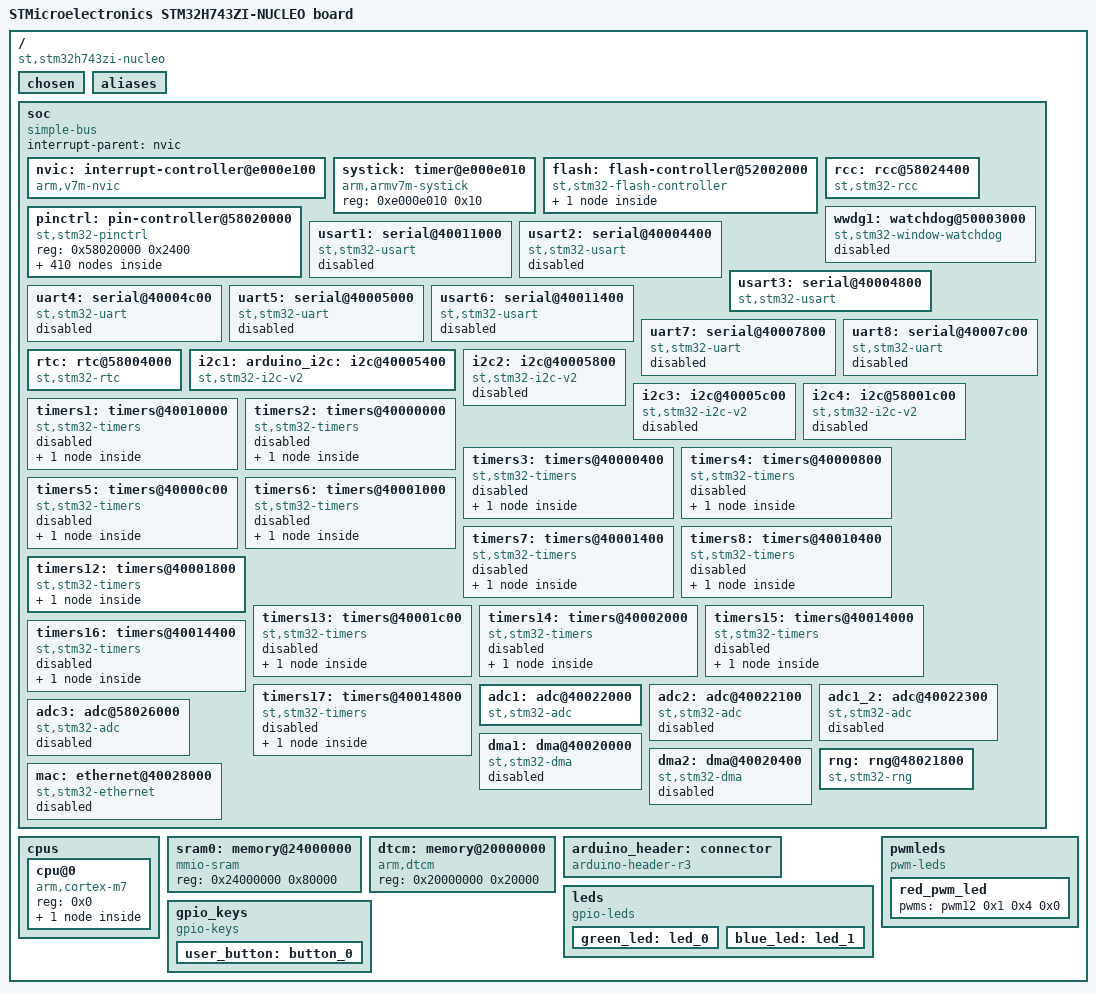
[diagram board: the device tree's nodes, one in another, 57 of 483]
/dts-v1/;

/ {
	#address-cells = < 0x1 >;
	#size-cells = < 0x1 >;
	model = "STMicroelectronics STM32H743ZI-NUCLEO board";
	compatible = "st,stm32h743zi-nucleo";
	chosen {
		zephyr,entropy = &rng;
		zephyr,flash-controller = &flash;
		zephyr,console = &usart3;
		zephyr,shell-uart = &usart3;
		zephyr,sram = &sram0;
		zephyr,flash = &flash0;
		zephyr,dtcm = &dtcm;
	};
	aliases {
		led0 = &green_led;
		led1 = &blue_led;
		pwm-led0 = &red_pwm_led;
		sw0 = &user_button;
	};
	soc {
		#address-cells = < 0x1 >;
		#size-cells = < 0x1 >;
		compatible = "simple-bus";
		interrupt-parent = < &nvic >;
		ranges;
		nvic: interrupt-controller@e000e100 {
			compatible = "arm,v7m-nvic";
			reg = < 0xe000e100 0xc00 >;
			interrupt-controller;
			#interrupt-cells = < 0x2 >;
			arm,num-irq-priority-bits = < 0x4 >;
			phandle = < 0x1 >;
		};
		systick: timer@e000e010 {
			compatible = "arm,armv7m-systick";
			reg = < 0xe000e010 0x10 >;
		};
		flash: flash-controller@52002000 {
			compatible = "st,stm32-flash-controller", "st,stm32h7-flash-controller";
			label = "FLASH_CTRL";
			reg = < 0x52002000 0x400 >;
			interrupts = < 0x4 0x0 >;
			#address-cells = < 0x1 >;
			#size-cells = < 0x1 >;
			flash0: flash@8000000 {
				compatible = "soc-nv-flash";
				label = "FLASH_STM32";
				reg = < 0x8000000 0x200000 >;
			};
		};
		rcc: rcc@58024400 {
			compatible = "st,stm32-rcc";
			#clock-cells = < 0x2 >;
			reg = < 0x58024400 0x400 >;
			label = "STM32_CLK_RCC";
			phandle = < 0x2 >;
		};
		pinctrl: pin-controller@58020000 {
			compatible = "st,stm32-pinctrl";
			#address-cells = < 0x1 >;
			#size-cells = < 0x1 >;
			reg = < 0x58020000 0x2400 >;
			gpioa: gpio@58020000 {
				compatible = "st,stm32-gpio";
				gpio-controller;
				#gpio-cells = < 0x2 >;
				reg = < 0x58020000 0x400 >;
				clocks = < &rcc 0x7 0x1 >;
				label = "GPIOA";
				phandle = < 0x9 >;
			};
			gpiob: gpio@58020400 {
				compatible = "st,stm32-gpio";
				gpio-controller;
				#gpio-cells = < 0x2 >;
				reg = < 0x58020400 0x400 >;
				clocks = < &rcc 0x7 0x2 >;
				label = "GPIOB";
				phandle = < 0xb >;
			};
			gpioc: gpio@58020800 {
				compatible = "st,stm32-gpio";
				gpio-controller;
				#gpio-cells = < 0x2 >;
				reg = < 0x58020800 0x400 >;
				clocks = < &rcc 0x7 0x4 >;
				label = "GPIOC";
				phandle = < 0xa >;
			};
			gpiod: gpio@58020C00 {
				compatible = "st,stm32-gpio";
				gpio-controller;
				#gpio-cells = < 0x2 >;
				reg = < 0x58020c00 0x400 >;
				clocks = < &rcc 0x7 0x8 >;
				label = "GPIOD";
				phandle = < 0xf >;
			};
			gpioe: gpio@58021000 {
				compatible = "st,stm32-gpio";
				gpio-controller;
				#gpio-cells = < 0x2 >;
				reg = < 0x58021000 0x400 >;
				clocks = < &rcc 0x7 0x10 >;
				label = "GPIOE";
				phandle = < 0xe >;
			};
			gpiof: gpio@58021400 {
				compatible = "st,stm32-gpio";
				gpio-controller;
				#gpio-cells = < 0x2 >;
				reg = < 0x58021400 0x400 >;
				clocks = < &rcc 0x7 0x20 >;
				label = "GPIOF";
				phandle = < 0xc >;
			};
			gpiog: gpio@58021800 {
				compatible = "st,stm32-gpio";
				gpio-controller;
				#gpio-cells = < 0x2 >;
				reg = < 0x58021800 0x400 >;
				clocks = < &rcc 0x7 0x40 >;
				label = "GPIOG";
				phandle = < 0xd >;
			};
			gpioh: gpio@58021C00 {
				compatible = "st,stm32-gpio";
				gpio-controller;
				#gpio-cells = < 0x2 >;
				reg = < 0x58021c00 0x400 >;
				clocks = < &rcc 0x7 0x80 >;
				label = "GPIOH";
			};
			gpioi: gpio@58022000 {
				compatible = "st,stm32-gpio";
				gpio-controller;
				#gpio-cells = < 0x2 >;
				reg = < 0x58022000 0x400 >;
				clocks = < &rcc 0x7 0x100 >;
				label = "GPIOI";
			};
			gpioj: gpio@58022400 {
				compatible = "st,stm32-gpio";
				gpio-controller;
				#gpio-cells = < 0x2 >;
				reg = < 0x58022400 0x400 >;
				clocks = < &rcc 0x7 0x200 >;
				label = "GPIOJ";
			};
			gpiok: gpio@58022800 {
				compatible = "st,stm32-gpio";
				gpio-controller;
				#gpio-cells = < 0x2 >;
				reg = < 0x58022800 0x400 >;
				clocks = < &rcc 0x7 0x400 >;
				label = "GPIOK";
			};
			adc1_inp16_pa0: adc1_inp16_pa0 {
				pinmux = < 0x10 >;
			};
			adc1_inn16_pa1: adc1_inn16_pa1 {
				pinmux = < 0x110 >;
			};
			adc1_inp17_pa1: adc1_inp17_pa1 {
				pinmux = < 0x110 >;
			};
			adc1_inp14_pa2: adc1_inp14_pa2 {
				pinmux = < 0x210 >;
			};
			adc1_inp15_pa3: adc1_inp15_pa3 {
				pinmux = < 0x310 >;
				phandle = < 0x8 >;
			};
			adc1_inp18_pa4: adc1_inp18_pa4 {
				pinmux = < 0x410 >;
			};
			adc1_inn18_pa5: adc1_inn18_pa5 {
				pinmux = < 0x510 >;
			};
			adc1_inp19_pa5: adc1_inp19_pa5 {
				pinmux = < 0x510 >;
			};
			adc1_inp3_pa6: adc1_inp3_pa6 {
				pinmux = < 0x610 >;
			};
			adc1_inn3_pa7: adc1_inn3_pa7 {
				pinmux = < 0x710 >;
			};
			adc1_inp7_pa7: adc1_inp7_pa7 {
				pinmux = < 0x710 >;
			};
			adc1_inn5_pb0: adc1_inn5_pb0 {
				pinmux = < 0x1010 >;
			};
			adc1_inp9_pb0: adc1_inp9_pb0 {
				pinmux = < 0x1010 >;
			};
			adc1_inp5_pb1: adc1_inp5_pb1 {
				pinmux = < 0x1110 >;
			};
			adc1_inp10_pc0: adc1_inp10_pc0 {
				pinmux = < 0x2010 >;
			};
			adc1_inn10_pc1: adc1_inn10_pc1 {
				pinmux = < 0x2110 >;
			};
			adc1_inp11_pc1: adc1_inp11_pc1 {
				pinmux = < 0x2110 >;
			};
			adc1_inp4_pc4: adc1_inp4_pc4 {
				pinmux = < 0x2410 >;
			};
			adc1_inn4_pc5: adc1_inn4_pc5 {
				pinmux = < 0x2510 >;
			};
			adc1_inp8_pc5: adc1_inp8_pc5 {
				pinmux = < 0x2510 >;
			};
			adc1_inp2_pf11: adc1_inp2_pf11 {
				pinmux = < 0x5b10 >;
			};
			adc1_inn2_pf12: adc1_inn2_pf12 {
				pinmux = < 0x5c10 >;
			};
			adc1_inp6_pf12: adc1_inp6_pf12 {
				pinmux = < 0x5c10 >;
			};
			adc2_inp14_pa2: adc2_inp14_pa2 {
				pinmux = < 0x210 >;
			};
			adc2_inp15_pa3: adc2_inp15_pa3 {
				pinmux = < 0x310 >;
			};
			adc2_inp18_pa4: adc2_inp18_pa4 {
				pinmux = < 0x410 >;
			};
			adc2_inn18_pa5: adc2_inn18_pa5 {
				pinmux = < 0x510 >;
			};
			adc2_inp19_pa5: adc2_inp19_pa5 {
				pinmux = < 0x510 >;
			};
			adc2_inp3_pa6: adc2_inp3_pa6 {
				pinmux = < 0x610 >;
			};
			adc2_inn3_pa7: adc2_inn3_pa7 {
				pinmux = < 0x710 >;
			};
			adc2_inp7_pa7: adc2_inp7_pa7 {
				pinmux = < 0x710 >;
			};
			adc2_inn5_pb0: adc2_inn5_pb0 {
				pinmux = < 0x1010 >;
			};
			adc2_inp9_pb0: adc2_inp9_pb0 {
				pinmux = < 0x1010 >;
			};
			adc2_inp5_pb1: adc2_inp5_pb1 {
				pinmux = < 0x1110 >;
			};
			adc2_inp10_pc0: adc2_inp10_pc0 {
				pinmux = < 0x2010 >;
			};
			adc2_inn10_pc1: adc2_inn10_pc1 {
				pinmux = < 0x2110 >;
			};
			adc2_inp11_pc1: adc2_inp11_pc1 {
				pinmux = < 0x2110 >;
			};
			adc2_inp4_pc4: adc2_inp4_pc4 {
				pinmux = < 0x2410 >;
			};
			adc2_inn4_pc5: adc2_inn4_pc5 {
				pinmux = < 0x2510 >;
			};
			adc2_inp8_pc5: adc2_inp8_pc5 {
				pinmux = < 0x2510 >;
			};
			adc2_inp2_pf13: adc2_inp2_pf13 {
				pinmux = < 0x5d10 >;
			};
			adc2_inn2_pf14: adc2_inn2_pf14 {
				pinmux = < 0x5e10 >;
			};
			adc2_inp6_pf14: adc2_inp6_pf14 {
				pinmux = < 0x5e10 >;
			};
			adc3_inp10_pc0: adc3_inp10_pc0 {
				pinmux = < 0x2010 >;
			};
			adc3_inn10_pc1: adc3_inn10_pc1 {
				pinmux = < 0x2110 >;
			};
			adc3_inp11_pc1: adc3_inp11_pc1 {
				pinmux = < 0x2110 >;
			};
			adc3_inn1_pc2: adc3_inn1_pc2 {
				pinmux = < 0x2210 >;
			};
			adc3_inp0_pc2: adc3_inp0_pc2 {
				pinmux = < 0x2210 >;
			};
			adc3_inp1_pc3: adc3_inp1_pc3 {
				pinmux = < 0x2310 >;
			};
			adc3_inp5_pf3: adc3_inp5_pf3 {
				pinmux = < 0x5310 >;
			};
			adc3_inn5_pf4: adc3_inn5_pf4 {
				pinmux = < 0x5410 >;
			};
			adc3_inp9_pf4: adc3_inp9_pf4 {
				pinmux = < 0x5410 >;
			};
			adc3_inp4_pf5: adc3_inp4_pf5 {
				pinmux = < 0x5510 >;
			};
			adc3_inn4_pf6: adc3_inn4_pf6 {
				pinmux = < 0x5610 >;
			};
			adc3_inp8_pf6: adc3_inp8_pf6 {
				pinmux = < 0x5610 >;
			};
			adc3_inp3_pf7: adc3_inp3_pf7 {
				pinmux = < 0x5710 >;
			};
			adc3_inn3_pf8: adc3_inn3_pf8 {
				pinmux = < 0x5810 >;
			};
			adc3_inp7_pf8: adc3_inp7_pf8 {
				pinmux = < 0x5810 >;
			};
			adc3_inp2_pf9: adc3_inp2_pf9 {
				pinmux = < 0x5910 >;
			};
			adc3_inn2_pf10: adc3_inn2_pf10 {
				pinmux = < 0x5a10 >;
			};
			adc3_inp6_pf10: adc3_inp6_pf10 {
				pinmux = < 0x5a10 >;
			};
			dac1_out1_pa4: dac1_out1_pa4 {
				pinmux = < 0x410 >;
			};
			dac1_out2_pa5: dac1_out2_pa5 {
				pinmux = < 0x510 >;
			};
			eth_col_pa3: eth_col_pa3 {
				pinmux = < 0x30b >;
				slew-rate = "very-high-speed";
			};
			eth_crs_pa0: eth_crs_pa0 {
				pinmux = < 0xb >;
				slew-rate = "very-high-speed";
			};
			eth_crs_dv_pa7: eth_crs_dv_pa7 {
				pinmux = < 0x70b >;
				slew-rate = "very-high-speed";
			};
			eth_mdc_pc1: eth_mdc_pc1 {
				pinmux = < 0x210b >;
				slew-rate = "very-high-speed";
			};
			eth_mdio_pa2: eth_mdio_pa2 {
				pinmux = < 0x20b >;
				slew-rate = "very-high-speed";
			};
			eth_pps_out_pb5: eth_pps_out_pb5 {
				pinmux = < 0x150b >;
				slew-rate = "very-high-speed";
			};
			eth_pps_out_pg8: eth_pps_out_pg8 {
				pinmux = < 0x680b >;
				slew-rate = "very-high-speed";
			};
			eth_ref_clk_pa1: eth_ref_clk_pa1 {
				pinmux = < 0x10b >;
				slew-rate = "very-high-speed";
			};
			eth_rxd0_pc4: eth_rxd0_pc4 {
				pinmux = < 0x240b >;
				slew-rate = "very-high-speed";
			};
			eth_rxd1_pc5: eth_rxd1_pc5 {
				pinmux = < 0x250b >;
				slew-rate = "very-high-speed";
			};
			eth_rxd2_pb0: eth_rxd2_pb0 {
				pinmux = < 0x100b >;
				slew-rate = "very-high-speed";
			};
			eth_rxd3_pb1: eth_rxd3_pb1 {
				pinmux = < 0x110b >;
				slew-rate = "very-high-speed";
			};
			eth_rx_clk_pa1: eth_rx_clk_pa1 {
				pinmux = < 0x10b >;
				slew-rate = "very-high-speed";
			};
			eth_rx_dv_pa7: eth_rx_dv_pa7 {
				pinmux = < 0x70b >;
				slew-rate = "very-high-speed";
			};
			eth_rx_er_pb10: eth_rx_er_pb10 {
				pinmux = < 0x1a0b >;
				slew-rate = "very-high-speed";
			};
			eth_txd0_pb12: eth_txd0_pb12 {
				pinmux = < 0x1c0b >;
				slew-rate = "very-high-speed";
			};
			eth_txd0_pg13: eth_txd0_pg13 {
				pinmux = < 0x6d0b >;
				slew-rate = "very-high-speed";
			};
			eth_txd1_pb13: eth_txd1_pb13 {
				pinmux = < 0x1d0b >;
				slew-rate = "very-high-speed";
			};
			eth_txd1_pg12: eth_txd1_pg12 {
				pinmux = < 0x6c0b >;
				slew-rate = "very-high-speed";
			};
			eth_txd1_pg14: eth_txd1_pg14 {
				pinmux = < 0x6e0b >;
				slew-rate = "very-high-speed";
			};
			eth_txd2_pc2: eth_txd2_pc2 {
				pinmux = < 0x220b >;
				slew-rate = "very-high-speed";
			};
			eth_txd3_pb8: eth_txd3_pb8 {
				pinmux = < 0x180b >;
				slew-rate = "very-high-speed";
			};
			eth_txd3_pe2: eth_txd3_pe2 {
				pinmux = < 0x420b >;
				slew-rate = "very-high-speed";
			};
			eth_tx_clk_pc3: eth_tx_clk_pc3 {
				pinmux = < 0x230b >;
				slew-rate = "very-high-speed";
			};
			eth_tx_en_pb11: eth_tx_en_pb11 {
				pinmux = < 0x1b0b >;
				slew-rate = "very-high-speed";
			};
			eth_tx_en_pg11: eth_tx_en_pg11 {
				pinmux = < 0x6b0b >;
				slew-rate = "very-high-speed";
			};
			fdcan1_rx_pa11: fdcan1_rx_pa11 {
				pinmux = < 0xb09 >;
			};
			fdcan1_rx_pb8: fdcan1_rx_pb8 {
				pinmux = < 0x1809 >;
			};
			fdcan1_rx_pd0: fdcan1_rx_pd0 {
				pinmux = < 0x3009 >;
			};
			fdcan2_rx_pb5: fdcan2_rx_pb5 {
				pinmux = < 0x1509 >;
			};
			fdcan2_rx_pb12: fdcan2_rx_pb12 {
				pinmux = < 0x1c09 >;
			};
			fdcan1_tx_pa12: fdcan1_tx_pa12 {
				pinmux = < 0xc09 >;
			};
			fdcan1_tx_pb9: fdcan1_tx_pb9 {
				pinmux = < 0x1909 >;
			};
			fdcan1_tx_pd1: fdcan1_tx_pd1 {
				pinmux = < 0x3109 >;
			};
			fdcan2_tx_pb6: fdcan2_tx_pb6 {
				pinmux = < 0x1609 >;
			};
			fdcan2_tx_pb13: fdcan2_tx_pb13 {
				pinmux = < 0x1d09 >;
			};
			i2c1_scl_pb6: i2c1_scl_pb6 {
				pinmux = < 0x1604 >;
				bias-pull-up;
				drive-open-drain;
			};
			i2c1_scl_pb8: i2c1_scl_pb8 {
				pinmux = < 0x1804 >;
				bias-pull-up;
				drive-open-drain;
				phandle = < 0x5 >;
			};
			i2c2_scl_pb10: i2c2_scl_pb10 {
				pinmux = < 0x1a04 >;
				bias-pull-up;
				drive-open-drain;
			};
			i2c2_scl_pf1: i2c2_scl_pf1 {
				pinmux = < 0x5104 >;
				bias-pull-up;
				drive-open-drain;
			};
			i2c3_scl_pa8: i2c3_scl_pa8 {
				pinmux = < 0x804 >;
				bias-pull-up;
				drive-open-drain;
			};
			i2c4_scl_pb6: i2c4_scl_pb6 {
				pinmux = < 0x1606 >;
				bias-pull-up;
				drive-open-drain;
			};
			i2c4_scl_pb8: i2c4_scl_pb8 {
				pinmux = < 0x1806 >;
				bias-pull-up;
				drive-open-drain;
			};
			i2c4_scl_pd12: i2c4_scl_pd12 {
				pinmux = < 0x3c04 >;
				bias-pull-up;
				drive-open-drain;
			};
			i2c4_scl_pf14: i2c4_scl_pf14 {
				pinmux = < 0x5e04 >;
				bias-pull-up;
				drive-open-drain;
			};
			i2c1_sda_pb7: i2c1_sda_pb7 {
				pinmux = < 0x1704 >;
				bias-pull-up;
				drive-open-drain;
			};
			i2c1_sda_pb9: i2c1_sda_pb9 {
				pinmux = < 0x1904 >;
				bias-pull-up;
				drive-open-drain;
				phandle = < 0x6 >;
			};
			i2c2_sda_pb11: i2c2_sda_pb11 {
				pinmux = < 0x1b04 >;
				bias-pull-up;
				drive-open-drain;
			};
			i2c2_sda_pf0: i2c2_sda_pf0 {
				pinmux = < 0x5004 >;
				bias-pull-up;
				drive-open-drain;
			};
			i2c3_sda_pc9: i2c3_sda_pc9 {
				pinmux = < 0x2904 >;
				bias-pull-up;
				drive-open-drain;
			};
			i2c4_sda_pb7: i2c4_sda_pb7 {
				pinmux = < 0x1706 >;
				bias-pull-up;
				drive-open-drain;
			};
			i2c4_sda_pb9: i2c4_sda_pb9 {
				pinmux = < 0x1906 >;
				bias-pull-up;
				drive-open-drain;
			};
			i2c4_sda_pd13: i2c4_sda_pd13 {
				pinmux = < 0x3d04 >;
				bias-pull-up;
				drive-open-drain;
			};
			i2c4_sda_pf15: i2c4_sda_pf15 {
				pinmux = < 0x5f04 >;
				bias-pull-up;
				drive-open-drain;
			};
			i2s1_ck_pa5: i2s1_ck_pa5 {
				pinmux = < 0x505 >;
				slew-rate = "very-high-speed";
			};
			i2s1_ck_pb3: i2s1_ck_pb3 {
				pinmux = < 0x1305 >;
				slew-rate = "very-high-speed";
			};
			i2s1_ck_pg11: i2s1_ck_pg11 {
				pinmux = < 0x6b05 >;
				slew-rate = "very-high-speed";
			};
			i2s2_ck_pa9: i2s2_ck_pa9 {
				pinmux = < 0x905 >;
				slew-rate = "very-high-speed";
			};
			i2s2_ck_pa12: i2s2_ck_pa12 {
				pinmux = < 0xc05 >;
				slew-rate = "very-high-speed";
			};
			i2s2_ck_pb10: i2s2_ck_pb10 {
				pinmux = < 0x1a05 >;
				slew-rate = "very-high-speed";
			};
			i2s2_ck_pb13: i2s2_ck_pb13 {
				pinmux = < 0x1d05 >;
				slew-rate = "very-high-speed";
			};
			i2s2_ck_pd3: i2s2_ck_pd3 {
				pinmux = < 0x3305 >;
				slew-rate = "very-high-speed";
			};
			i2s3_ck_pb3: i2s3_ck_pb3 {
				pinmux = < 0x1306 >;
				slew-rate = "very-high-speed";
			};
			i2s3_ck_pc10: i2s3_ck_pc10 {
				pinmux = < 0x2a06 >;
				slew-rate = "very-high-speed";
			};
			i2s1_ws_pa4: i2s1_ws_pa4 {
				pinmux = < 0x405 >;
			};
			i2s1_ws_pa15: i2s1_ws_pa15 {
				pinmux = < 0xf05 >;
			};
			i2s1_ws_pg10: i2s1_ws_pg10 {
				pinmux = < 0x6a05 >;
			};
			i2s2_ws_pa11: i2s2_ws_pa11 {
				pinmux = < 0xb05 >;
			};
			i2s2_ws_pb4: i2s2_ws_pb4 {
				pinmux = < 0x1407 >;
			};
			i2s2_ws_pb9: i2s2_ws_pb9 {
				pinmux = < 0x1905 >;
			};
			i2s2_ws_pb12: i2s2_ws_pb12 {
				pinmux = < 0x1c05 >;
			};
			i2s3_ws_pa4: i2s3_ws_pa4 {
				pinmux = < 0x406 >;
			};
			i2s3_ws_pa15: i2s3_ws_pa15 {
				pinmux = < 0xf06 >;
			};
			sdmmc1_ckin_pb8: sdmmc1_ckin_pb8 {
				pinmux = < 0x1807 >;
				slew-rate = "very-high-speed";
			};
			sdmmc1_d4_pb8: sdmmc1_d4_pb8 {
				pinmux = < 0x180c >;
				slew-rate = "very-high-speed";
			};
			sdmmc1_cdir_pb9: sdmmc1_cdir_pb9 {
				pinmux = < 0x1907 >;
				slew-rate = "very-high-speed";
			};
			sdmmc1_d5_pb9: sdmmc1_d5_pb9 {
				pinmux = < 0x190c >;
				slew-rate = "very-high-speed";
			};
			sdmmc1_d0dir_pc6: sdmmc1_d0dir_pc6 {
				pinmux = < 0x2608 >;
				slew-rate = "very-high-speed";
			};
			sdmmc1_d6_pc6: sdmmc1_d6_pc6 {
				pinmux = < 0x260c >;
				slew-rate = "very-high-speed";
			};
			sdmmc1_d123dir_pc7: sdmmc1_d123dir_pc7 {
				pinmux = < 0x2708 >;
				slew-rate = "very-high-speed";
			};
			sdmmc1_d7_pc7: sdmmc1_d7_pc7 {
				pinmux = < 0x270c >;
				slew-rate = "very-high-speed";
			};
			sdmmc1_d0_pc8: sdmmc1_d0_pc8 {
				pinmux = < 0x280c >;
				slew-rate = "very-high-speed";
			};
			sdmmc1_d1_pc9: sdmmc1_d1_pc9 {
				pinmux = < 0x290c >;
				slew-rate = "very-high-speed";
			};
			sdmmc1_d2_pc10: sdmmc1_d2_pc10 {
				pinmux = < 0x2a0c >;
				slew-rate = "very-high-speed";
			};
			sdmmc1_d3_pc11: sdmmc1_d3_pc11 {
				pinmux = < 0x2b0c >;
				slew-rate = "very-high-speed";
			};
			sdmmc1_ck_pc12: sdmmc1_ck_pc12 {
				pinmux = < 0x2c0c >;
				slew-rate = "very-high-speed";
			};
			sdmmc1_cmd_pd2: sdmmc1_cmd_pd2 {
				pinmux = < 0x320c >;
				slew-rate = "very-high-speed";
			};
			sdmmc2_cmd_pa0: sdmmc2_cmd_pa0 {
				pinmux = < 0x9 >;
				slew-rate = "very-high-speed";
			};
			sdmmc2_d2_pb3: sdmmc2_d2_pb3 {
				pinmux = < 0x1309 >;
				slew-rate = "very-high-speed";
			};
			sdmmc2_d3_pb4: sdmmc2_d3_pb4 {
				pinmux = < 0x1409 >;
				slew-rate = "very-high-speed";
			};
			sdmmc2_d4_pb8: sdmmc2_d4_pb8 {
				pinmux = < 0x180a >;
				slew-rate = "very-high-speed";
			};
			sdmmc2_d5_pb9: sdmmc2_d5_pb9 {
				pinmux = < 0x190a >;
				slew-rate = "very-high-speed";
			};
			sdmmc2_d0_pb14: sdmmc2_d0_pb14 {
				pinmux = < 0x1e09 >;
				slew-rate = "very-high-speed";
			};
			sdmmc2_d1_pb15: sdmmc2_d1_pb15 {
				pinmux = < 0x1f09 >;
				slew-rate = "very-high-speed";
			};
			sdmmc2_ck_pc1: sdmmc2_ck_pc1 {
				pinmux = < 0x2109 >;
				slew-rate = "very-high-speed";
			};
			sdmmc2_d6_pc6: sdmmc2_d6_pc6 {
				pinmux = < 0x260a >;
				slew-rate = "very-high-speed";
			};
			sdmmc2_d7_pc7: sdmmc2_d7_pc7 {
				pinmux = < 0x270a >;
				slew-rate = "very-high-speed";
			};
			sdmmc2_ck_pd6: sdmmc2_ck_pd6 {
				pinmux = < 0x360b >;
				slew-rate = "very-high-speed";
			};
			sdmmc2_cmd_pd7: sdmmc2_cmd_pd7 {
				pinmux = < 0x370b >;
				slew-rate = "very-high-speed";
			};
			sdmmc2_d2_pg11: sdmmc2_d2_pg11 {
				pinmux = < 0x6b0a >;
				slew-rate = "very-high-speed";
			};
			spi1_miso_pa6: spi1_miso_pa6 {
				pinmux = < 0x605 >;
				bias-pull-down;
			};
			spi1_miso_pb4: spi1_miso_pb4 {
				pinmux = < 0x1405 >;
				bias-pull-down;
			};
			spi1_miso_pg9: spi1_miso_pg9 {
				pinmux = < 0x6905 >;
				bias-pull-down;
			};
			spi2_miso_pb14: spi2_miso_pb14 {
				pinmux = < 0x1e05 >;
				bias-pull-down;
			};
			spi2_miso_pc2: spi2_miso_pc2 {
				pinmux = < 0x2205 >;
				bias-pull-down;
			};
			spi3_miso_pb4: spi3_miso_pb4 {
				pinmux = < 0x1406 >;
				bias-pull-down;
			};
			spi3_miso_pc11: spi3_miso_pc11 {
				pinmux = < 0x2b06 >;
				bias-pull-down;
			};
			spi4_miso_pe5: spi4_miso_pe5 {
				pinmux = < 0x4505 >;
				bias-pull-down;
			};
			spi4_miso_pe13: spi4_miso_pe13 {
				pinmux = < 0x4d05 >;
				bias-pull-down;
			};
			spi5_miso_pf8: spi5_miso_pf8 {
				pinmux = < 0x5805 >;
				bias-pull-down;
			};
			spi6_miso_pa6: spi6_miso_pa6 {
				pinmux = < 0x608 >;
				bias-pull-down;
			};
			spi6_miso_pb4: spi6_miso_pb4 {
				pinmux = < 0x1408 >;
				bias-pull-down;
			};
			spi6_miso_pg12: spi6_miso_pg12 {
				pinmux = < 0x6c05 >;
				bias-pull-down;
			};
			spi1_mosi_pa7: spi1_mosi_pa7 {
				pinmux = < 0x705 >;
				bias-pull-down;
			};
			spi1_mosi_pb5: spi1_mosi_pb5 {
				pinmux = < 0x1505 >;
				bias-pull-down;
			};
			spi1_mosi_pd7: spi1_mosi_pd7 {
				pinmux = < 0x3705 >;
				bias-pull-down;
			};
			spi2_mosi_pb15: spi2_mosi_pb15 {
				pinmux = < 0x1f05 >;
				bias-pull-down;
			};
			spi2_mosi_pc1: spi2_mosi_pc1 {
				pinmux = < 0x2105 >;
				bias-pull-down;
			};
			spi2_mosi_pc3: spi2_mosi_pc3 {
				pinmux = < 0x2305 >;
				bias-pull-down;
			};
			spi3_mosi_pb2: spi3_mosi_pb2 {
				pinmux = < 0x1207 >;
				bias-pull-down;
			};
			spi3_mosi_pb5: spi3_mosi_pb5 {
				pinmux = < 0x1507 >;
				bias-pull-down;
			};
			spi3_mosi_pc12: spi3_mosi_pc12 {
				pinmux = < 0x2c06 >;
				bias-pull-down;
			};
			spi3_mosi_pd6: spi3_mosi_pd6 {
				pinmux = < 0x3605 >;
				bias-pull-down;
			};
			spi4_mosi_pe6: spi4_mosi_pe6 {
				pinmux = < 0x4605 >;
				bias-pull-down;
			};
			spi4_mosi_pe14: spi4_mosi_pe14 {
				pinmux = < 0x4e05 >;
				bias-pull-down;
			};
			spi5_mosi_pf9: spi5_mosi_pf9 {
				pinmux = < 0x5905 >;
				bias-pull-down;
			};
			spi5_mosi_pf11: spi5_mosi_pf11 {
				pinmux = < 0x5b05 >;
				bias-pull-down;
			};
			spi6_mosi_pa7: spi6_mosi_pa7 {
				pinmux = < 0x708 >;
				bias-pull-down;
			};
			spi6_mosi_pb5: spi6_mosi_pb5 {
				pinmux = < 0x1508 >;
				bias-pull-down;
			};
			spi6_mosi_pg14: spi6_mosi_pg14 {
				pinmux = < 0x6e05 >;
				bias-pull-down;
			};
			spi1_nss_pa4: spi1_nss_pa4 {
				pinmux = < 0x405 >;
				bias-pull-up;
			};
			spi1_nss_pa15: spi1_nss_pa15 {
				pinmux = < 0xf05 >;
				bias-pull-up;
			};
			spi1_nss_pg10: spi1_nss_pg10 {
				pinmux = < 0x6a05 >;
				bias-pull-up;
			};
			spi2_nss_pa11: spi2_nss_pa11 {
				pinmux = < 0xb05 >;
				bias-pull-up;
			};
			spi2_nss_pb4: spi2_nss_pb4 {
				pinmux = < 0x1407 >;
				bias-pull-up;
			};
			spi2_nss_pb9: spi2_nss_pb9 {
				pinmux = < 0x1905 >;
				bias-pull-up;
			};
			spi2_nss_pb12: spi2_nss_pb12 {
				pinmux = < 0x1c05 >;
				bias-pull-up;
			};
			spi3_nss_pa4: spi3_nss_pa4 {
				pinmux = < 0x406 >;
				bias-pull-up;
			};
			spi3_nss_pa15: spi3_nss_pa15 {
				pinmux = < 0xf06 >;
				bias-pull-up;
			};
			spi4_nss_pe4: spi4_nss_pe4 {
				pinmux = < 0x4405 >;
				bias-pull-up;
			};
			spi4_nss_pe11: spi4_nss_pe11 {
				pinmux = < 0x4b05 >;
				bias-pull-up;
			};
			spi5_nss_pf6: spi5_nss_pf6 {
				pinmux = < 0x5605 >;
				bias-pull-up;
			};
			spi6_nss_pa4: spi6_nss_pa4 {
				pinmux = < 0x408 >;
				bias-pull-up;
			};
			spi6_nss_pa15: spi6_nss_pa15 {
				pinmux = < 0xf07 >;
				bias-pull-up;
			};
			spi6_nss_pg8: spi6_nss_pg8 {
				pinmux = < 0x6805 >;
				bias-pull-up;
			};
			spi1_sck_pa5: spi1_sck_pa5 {
				pinmux = < 0x505 >;
				slew-rate = "very-high-speed";
			};
			spi1_sck_pb3: spi1_sck_pb3 {
				pinmux = < 0x1305 >;
				slew-rate = "very-high-speed";
			};
			spi1_sck_pg11: spi1_sck_pg11 {
				pinmux = < 0x6b05 >;
				slew-rate = "very-high-speed";
			};
			spi2_sck_pa9: spi2_sck_pa9 {
				pinmux = < 0x905 >;
				slew-rate = "very-high-speed";
			};
			spi2_sck_pa12: spi2_sck_pa12 {
				pinmux = < 0xc05 >;
				slew-rate = "very-high-speed";
			};
			spi2_sck_pb10: spi2_sck_pb10 {
				pinmux = < 0x1a05 >;
				slew-rate = "very-high-speed";
			};
			spi2_sck_pb13: spi2_sck_pb13 {
				pinmux = < 0x1d05 >;
				slew-rate = "very-high-speed";
			};
			spi2_sck_pd3: spi2_sck_pd3 {
				pinmux = < 0x3305 >;
				slew-rate = "very-high-speed";
			};
			spi3_sck_pb3: spi3_sck_pb3 {
				pinmux = < 0x1306 >;
				slew-rate = "very-high-speed";
			};
			spi3_sck_pc10: spi3_sck_pc10 {
				pinmux = < 0x2a06 >;
				slew-rate = "very-high-speed";
			};
			spi4_sck_pe2: spi4_sck_pe2 {
				pinmux = < 0x4205 >;
				slew-rate = "very-high-speed";
			};
			spi4_sck_pe12: spi4_sck_pe12 {
				pinmux = < 0x4c05 >;
				slew-rate = "very-high-speed";
			};
			spi5_sck_pf7: spi5_sck_pf7 {
				pinmux = < 0x5705 >;
				slew-rate = "very-high-speed";
			};
			spi6_sck_pa5: spi6_sck_pa5 {
				pinmux = < 0x508 >;
				slew-rate = "very-high-speed";
			};
			spi6_sck_pb3: spi6_sck_pb3 {
				pinmux = < 0x1308 >;
				slew-rate = "very-high-speed";
			};
			spi6_sck_pg13: spi6_sck_pg13 {
				pinmux = < 0x6d05 >;
				slew-rate = "very-high-speed";
			};
			tim1_ch1n_pwm_pa7: tim1_ch1n_pwm_pa7 {
				pinmux = < 0x701 >;
			};
			tim1_ch1_pwm_pa8: tim1_ch1_pwm_pa8 {
				pinmux = < 0x801 >;
			};
			tim1_ch2_pwm_pa9: tim1_ch2_pwm_pa9 {
				pinmux = < 0x901 >;
			};
			tim1_ch3_pwm_pa10: tim1_ch3_pwm_pa10 {
				pinmux = < 0xa01 >;
			};
			tim1_ch4_pwm_pa11: tim1_ch4_pwm_pa11 {
				pinmux = < 0xb01 >;
			};
			tim1_ch2n_pwm_pb0: tim1_ch2n_pwm_pb0 {
				pinmux = < 0x1001 >;
			};
			tim1_ch3n_pwm_pb1: tim1_ch3n_pwm_pb1 {
				pinmux = < 0x1101 >;
			};
			tim1_ch1n_pwm_pb13: tim1_ch1n_pwm_pb13 {
				pinmux = < 0x1d01 >;
			};
			tim1_ch2n_pwm_pb14: tim1_ch2n_pwm_pb14 {
				pinmux = < 0x1e01 >;
			};
			tim1_ch3n_pwm_pb15: tim1_ch3n_pwm_pb15 {
				pinmux = < 0x1f01 >;
			};
			tim1_ch1n_pwm_pe8: tim1_ch1n_pwm_pe8 {
				pinmux = < 0x4801 >;
			};
			tim1_ch1_pwm_pe9: tim1_ch1_pwm_pe9 {
				pinmux = < 0x4901 >;
			};
			tim1_ch2n_pwm_pe10: tim1_ch2n_pwm_pe10 {
				pinmux = < 0x4a01 >;
			};
			tim1_ch2_pwm_pe11: tim1_ch2_pwm_pe11 {
				pinmux = < 0x4b01 >;
			};
			tim1_ch3n_pwm_pe12: tim1_ch3n_pwm_pe12 {
				pinmux = < 0x4c01 >;
			};
			tim1_ch3_pwm_pe13: tim1_ch3_pwm_pe13 {
				pinmux = < 0x4d01 >;
			};
			tim1_ch4_pwm_pe14: tim1_ch4_pwm_pe14 {
				pinmux = < 0x4e01 >;
			};
			tim2_ch1_pwm_pa0: tim2_ch1_pwm_pa0 {
				pinmux = < 0x1 >;
			};
			tim2_ch2_pwm_pa1: tim2_ch2_pwm_pa1 {
				pinmux = < 0x101 >;
			};
			tim2_ch3_pwm_pa2: tim2_ch3_pwm_pa2 {
				pinmux = < 0x201 >;
			};
			tim2_ch4_pwm_pa3: tim2_ch4_pwm_pa3 {
				pinmux = < 0x301 >;
			};
			tim2_ch1_pwm_pa5: tim2_ch1_pwm_pa5 {
				pinmux = < 0x501 >;
			};
			tim2_ch1_pwm_pa15: tim2_ch1_pwm_pa15 {
				pinmux = < 0xf01 >;
			};
			tim2_ch2_pwm_pb3: tim2_ch2_pwm_pb3 {
				pinmux = < 0x1301 >;
			};
			tim2_ch3_pwm_pb10: tim2_ch3_pwm_pb10 {
				pinmux = < 0x1a01 >;
			};
			tim2_ch4_pwm_pb11: tim2_ch4_pwm_pb11 {
				pinmux = < 0x1b01 >;
			};
			tim12_ch1_pwm_pb14: tim12_ch1_pwm_pb14 {
				pinmux = < 0x1e02 >;
				phandle = < 0x7 >;
			};
			tim12_ch2_pwm_pb15: tim12_ch2_pwm_pb15 {
				pinmux = < 0x1f02 >;
			};
			tim13_ch1_pwm_pa6: tim13_ch1_pwm_pa6 {
				pinmux = < 0x609 >;
			};
			tim3_ch1_pwm_pa6: tim3_ch1_pwm_pa6 {
				pinmux = < 0x602 >;
			};
			tim3_ch2_pwm_pa7: tim3_ch2_pwm_pa7 {
				pinmux = < 0x702 >;
			};
			tim3_ch3_pwm_pb0: tim3_ch3_pwm_pb0 {
				pinmux = < 0x1002 >;
			};
			tim3_ch4_pwm_pb1: tim3_ch4_pwm_pb1 {
				pinmux = < 0x1102 >;
			};
			tim3_ch1_pwm_pb4: tim3_ch1_pwm_pb4 {
				pinmux = < 0x1402 >;
			};
			tim3_ch2_pwm_pb5: tim3_ch2_pwm_pb5 {
				pinmux = < 0x1502 >;
			};
			tim3_ch1_pwm_pc6: tim3_ch1_pwm_pc6 {
				pinmux = < 0x2602 >;
			};
			tim3_ch2_pwm_pc7: tim3_ch2_pwm_pc7 {
				pinmux = < 0x2702 >;
			};
			tim3_ch3_pwm_pc8: tim3_ch3_pwm_pc8 {
				pinmux = < 0x2802 >;
			};
			tim3_ch4_pwm_pc9: tim3_ch4_pwm_pc9 {
				pinmux = < 0x2902 >;
			};
			tim13_ch1_pwm_pf8: tim13_ch1_pwm_pf8 {
				pinmux = < 0x5809 >;
			};
			tim14_ch1_pwm_pa7: tim14_ch1_pwm_pa7 {
				pinmux = < 0x709 >;
			};
			tim4_ch1_pwm_pb6: tim4_ch1_pwm_pb6 {
				pinmux = < 0x1602 >;
			};
			tim4_ch2_pwm_pb7: tim4_ch2_pwm_pb7 {
				pinmux = < 0x1702 >;
			};
			tim4_ch3_pwm_pb8: tim4_ch3_pwm_pb8 {
				pinmux = < 0x1802 >;
			};
			tim4_ch4_pwm_pb9: tim4_ch4_pwm_pb9 {
				pinmux = < 0x1902 >;
			};
			tim4_ch1_pwm_pd12: tim4_ch1_pwm_pd12 {
				pinmux = < 0x3c02 >;
			};
			tim4_ch2_pwm_pd13: tim4_ch2_pwm_pd13 {
				pinmux = < 0x3d02 >;
			};
			tim4_ch3_pwm_pd14: tim4_ch3_pwm_pd14 {
				pinmux = < 0x3e02 >;
			};
			tim4_ch4_pwm_pd15: tim4_ch4_pwm_pd15 {
				pinmux = < 0x3f02 >;
			};
			tim14_ch1_pwm_pf9: tim14_ch1_pwm_pf9 {
				pinmux = < 0x5909 >;
			};
			tim5_ch1_pwm_pa0: tim5_ch1_pwm_pa0 {
				pinmux = < 0x2 >;
			};
			tim15_ch1n_pwm_pa1: tim15_ch1n_pwm_pa1 {
				pinmux = < 0x104 >;
			};
			tim5_ch2_pwm_pa1: tim5_ch2_pwm_pa1 {
				pinmux = < 0x102 >;
			};
			tim15_ch1_pwm_pa2: tim15_ch1_pwm_pa2 {
				pinmux = < 0x204 >;
			};
			tim5_ch3_pwm_pa2: tim5_ch3_pwm_pa2 {
				pinmux = < 0x202 >;
			};
			tim15_ch2_pwm_pa3: tim15_ch2_pwm_pa3 {
				pinmux = < 0x304 >;
			};
			tim5_ch4_pwm_pa3: tim5_ch4_pwm_pa3 {
				pinmux = < 0x302 >;
			};
			tim15_ch1n_pwm_pe4: tim15_ch1n_pwm_pe4 {
				pinmux = < 0x4404 >;
			};
			tim15_ch1_pwm_pe5: tim15_ch1_pwm_pe5 {
				pinmux = < 0x4504 >;
			};
			tim15_ch2_pwm_pe6: tim15_ch2_pwm_pe6 {
				pinmux = < 0x4604 >;
			};
			tim16_ch1n_pwm_pb6: tim16_ch1n_pwm_pb6 {
				pinmux = < 0x1601 >;
			};
			tim16_ch1_pwm_pb8: tim16_ch1_pwm_pb8 {
				pinmux = < 0x1801 >;
			};
			tim16_ch1_pwm_pf6: tim16_ch1_pwm_pf6 {
				pinmux = < 0x5601 >;
			};
			tim16_ch1n_pwm_pf8: tim16_ch1n_pwm_pf8 {
				pinmux = < 0x5801 >;
			};
			tim17_ch1n_pwm_pb7: tim17_ch1n_pwm_pb7 {
				pinmux = < 0x1701 >;
			};
			tim17_ch1_pwm_pb9: tim17_ch1_pwm_pb9 {
				pinmux = < 0x1901 >;
			};
			tim17_ch1_pwm_pf7: tim17_ch1_pwm_pf7 {
				pinmux = < 0x5701 >;
			};
			tim17_ch1n_pwm_pf9: tim17_ch1n_pwm_pf9 {
				pinmux = < 0x5901 >;
			};
			tim8_ch1n_pwm_pa5: tim8_ch1n_pwm_pa5 {
				pinmux = < 0x503 >;
			};
			tim8_ch1n_pwm_pa7: tim8_ch1n_pwm_pa7 {
				pinmux = < 0x703 >;
			};
			tim8_ch2n_pwm_pb0: tim8_ch2n_pwm_pb0 {
				pinmux = < 0x1003 >;
			};
			tim8_ch3n_pwm_pb1: tim8_ch3n_pwm_pb1 {
				pinmux = < 0x1103 >;
			};
			tim8_ch2n_pwm_pb14: tim8_ch2n_pwm_pb14 {
				pinmux = < 0x1e03 >;
			};
			tim8_ch3n_pwm_pb15: tim8_ch3n_pwm_pb15 {
				pinmux = < 0x1f03 >;
			};
			tim8_ch1_pwm_pc6: tim8_ch1_pwm_pc6 {
				pinmux = < 0x2603 >;
			};
			tim8_ch2_pwm_pc7: tim8_ch2_pwm_pc7 {
				pinmux = < 0x2703 >;
			};
			tim8_ch3_pwm_pc8: tim8_ch3_pwm_pc8 {
				pinmux = < 0x2803 >;
			};
			tim8_ch4_pwm_pc9: tim8_ch4_pwm_pc9 {
				pinmux = < 0x2903 >;
			};
			lpuart1_cts_pa11: lpuart1_cts_pa11 {
				pinmux = < 0xb03 >;
				bias-pull-up;
				drive-open-drain;
			};
			usart1_cts_pa11: usart1_cts_pa11 {
				pinmux = < 0xb07 >;
				bias-pull-up;
				drive-open-drain;
			};
			usart2_cts_pa0: usart2_cts_pa0 {
				pinmux = < 0x7 >;
				bias-pull-up;
				drive-open-drain;
			};
			usart2_cts_pd3: usart2_cts_pd3 {
				pinmux = < 0x3307 >;
				bias-pull-up;
				drive-open-drain;
			};
			usart3_cts_pb13: usart3_cts_pb13 {
				pinmux = < 0x1d07 >;
				bias-pull-up;
				drive-open-drain;
			};
			usart3_cts_pd11: usart3_cts_pd11 {
				pinmux = < 0x3b07 >;
				bias-pull-up;
				drive-open-drain;
			};
			uart4_cts_pb0: uart4_cts_pb0 {
				pinmux = < 0x1008 >;
				bias-pull-up;
				drive-open-drain;
			};
			uart4_cts_pb15: uart4_cts_pb15 {
				pinmux = < 0x1f08 >;
				bias-pull-up;
				drive-open-drain;
			};
			uart5_cts_pc9: uart5_cts_pc9 {
				pinmux = < 0x2908 >;
				bias-pull-up;
				drive-open-drain;
			};
			usart6_cts_pg13: usart6_cts_pg13 {
				pinmux = < 0x6d07 >;
				bias-pull-up;
				drive-open-drain;
			};
			usart6_cts_pg15: usart6_cts_pg15 {
				pinmux = < 0x6f07 >;
				bias-pull-up;
				drive-open-drain;
			};
			uart7_cts_pe10: uart7_cts_pe10 {
				pinmux = < 0x4a07 >;
				bias-pull-up;
				drive-open-drain;
			};
			uart7_cts_pf9: uart7_cts_pf9 {
				pinmux = < 0x5907 >;
				bias-pull-up;
				drive-open-drain;
			};
			uart8_cts_pd14: uart8_cts_pd14 {
				pinmux = < 0x3e08 >;
				bias-pull-up;
				drive-open-drain;
			};
			lpuart1_rts_pa12: lpuart1_rts_pa12 {
				pinmux = < 0xc03 >;
				bias-pull-up;
				drive-open-drain;
			};
			usart1_rts_pa12: usart1_rts_pa12 {
				pinmux = < 0xc07 >;
				bias-pull-up;
				drive-open-drain;
			};
			usart2_rts_pa1: usart2_rts_pa1 {
				pinmux = < 0x107 >;
				bias-pull-up;
				drive-open-drain;
			};
			usart2_rts_pd4: usart2_rts_pd4 {
				pinmux = < 0x3407 >;
				bias-pull-up;
				drive-open-drain;
			};
			usart3_rts_pb14: usart3_rts_pb14 {
				pinmux = < 0x1e07 >;
				bias-pull-up;
				drive-open-drain;
			};
			usart3_rts_pd12: usart3_rts_pd12 {
				pinmux = < 0x3c07 >;
				bias-pull-up;
				drive-open-drain;
			};
			uart4_rts_pa15: uart4_rts_pa15 {
				pinmux = < 0xf08 >;
				bias-pull-up;
				drive-open-drain;
			};
			uart4_rts_pb14: uart4_rts_pb14 {
				pinmux = < 0x1e08 >;
				bias-pull-up;
				drive-open-drain;
			};
			uart5_rts_pc8: uart5_rts_pc8 {
				pinmux = < 0x2808 >;
				bias-pull-up;
				drive-open-drain;
			};
			usart6_rts_pg8: usart6_rts_pg8 {
				pinmux = < 0x6807 >;
				bias-pull-up;
				drive-open-drain;
			};
			usart6_rts_pg12: usart6_rts_pg12 {
				pinmux = < 0x6c07 >;
				bias-pull-up;
				drive-open-drain;
			};
			uart7_rts_pe9: uart7_rts_pe9 {
				pinmux = < 0x4907 >;
				bias-pull-up;
				drive-open-drain;
			};
			uart7_rts_pf8: uart7_rts_pf8 {
				pinmux = < 0x5807 >;
				bias-pull-up;
				drive-open-drain;
			};
			uart8_rts_pd15: uart8_rts_pd15 {
				pinmux = < 0x3f08 >;
				bias-pull-up;
				drive-open-drain;
			};
			lpuart1_rx_pa10: lpuart1_rx_pa10 {
				pinmux = < 0xa03 >;
			};
			usart1_rx_pa10: usart1_rx_pa10 {
				pinmux = < 0xa07 >;
			};
			lpuart1_rx_pb7: lpuart1_rx_pb7 {
				pinmux = < 0x1708 >;
			};
			usart1_rx_pb7: usart1_rx_pb7 {
				pinmux = < 0x1707 >;
			};
			usart1_rx_pb15: usart1_rx_pb15 {
				pinmux = < 0x1f04 >;
			};
			usart2_rx_pa3: usart2_rx_pa3 {
				pinmux = < 0x307 >;
			};
			usart2_rx_pd6: usart2_rx_pd6 {
				pinmux = < 0x3607 >;
			};
			usart3_rx_pb11: usart3_rx_pb11 {
				pinmux = < 0x1b07 >;
			};
			usart3_rx_pc11: usart3_rx_pc11 {
				pinmux = < 0x2b07 >;
			};
			usart3_rx_pd9: usart3_rx_pd9 {
				pinmux = < 0x3907 >;
				phandle = < 0x4 >;
			};
			uart4_rx_pa1: uart4_rx_pa1 {
				pinmux = < 0x108 >;
			};
			uart4_rx_pa11: uart4_rx_pa11 {
				pinmux = < 0xb06 >;
			};
			uart4_rx_pb8: uart4_rx_pb8 {
				pinmux = < 0x1808 >;
			};
			uart4_rx_pc11: uart4_rx_pc11 {
				pinmux = < 0x2b08 >;
			};
			uart4_rx_pd0: uart4_rx_pd0 {
				pinmux = < 0x3008 >;
			};
			uart5_rx_pb5: uart5_rx_pb5 {
				pinmux = < 0x150e >;
			};
			uart5_rx_pb12: uart5_rx_pb12 {
				pinmux = < 0x1c0e >;
			};
			uart5_rx_pd2: uart5_rx_pd2 {
				pinmux = < 0x3208 >;
			};
			usart6_rx_pc7: usart6_rx_pc7 {
				pinmux = < 0x2707 >;
			};
			usart6_rx_pg9: usart6_rx_pg9 {
				pinmux = < 0x6907 >;
			};
			uart7_rx_pa8: uart7_rx_pa8 {
				pinmux = < 0x80b >;
			};
			uart7_rx_pb3: uart7_rx_pb3 {
				pinmux = < 0x130b >;
			};
			uart7_rx_pe7: uart7_rx_pe7 {
				pinmux = < 0x4707 >;
			};
			uart7_rx_pf6: uart7_rx_pf6 {
				pinmux = < 0x5607 >;
			};
			uart8_rx_pe0: uart8_rx_pe0 {
				pinmux = < 0x4008 >;
			};
			lpuart1_tx_pa9: lpuart1_tx_pa9 {
				pinmux = < 0x903 >;
				bias-pull-up;
			};
			usart1_tx_pa9: usart1_tx_pa9 {
				pinmux = < 0x907 >;
				bias-pull-up;
			};
			lpuart1_tx_pb6: lpuart1_tx_pb6 {
				pinmux = < 0x1608 >;
				bias-pull-up;
			};
			usart1_tx_pb6: usart1_tx_pb6 {
				pinmux = < 0x1607 >;
				bias-pull-up;
			};
			usart1_tx_pb14: usart1_tx_pb14 {
				pinmux = < 0x1e04 >;
				bias-pull-up;
			};
			usart2_tx_pa2: usart2_tx_pa2 {
				pinmux = < 0x207 >;
				bias-pull-up;
			};
			usart2_tx_pd5: usart2_tx_pd5 {
				pinmux = < 0x3507 >;
				bias-pull-up;
			};
			usart3_tx_pb10: usart3_tx_pb10 {
				pinmux = < 0x1a07 >;
				bias-pull-up;
			};
			usart3_tx_pc10: usart3_tx_pc10 {
				pinmux = < 0x2a07 >;
				bias-pull-up;
			};
			usart3_tx_pd8: usart3_tx_pd8 {
				pinmux = < 0x3807 >;
				bias-pull-up;
				phandle = < 0x3 >;
			};
			uart4_tx_pa0: uart4_tx_pa0 {
				pinmux = < 0x8 >;
				bias-pull-up;
			};
			uart4_tx_pa12: uart4_tx_pa12 {
				pinmux = < 0xc06 >;
				bias-pull-up;
			};
			uart4_tx_pb9: uart4_tx_pb9 {
				pinmux = < 0x1908 >;
				bias-pull-up;
			};
			uart4_tx_pc10: uart4_tx_pc10 {
				pinmux = < 0x2a08 >;
				bias-pull-up;
			};
			uart4_tx_pd1: uart4_tx_pd1 {
				pinmux = < 0x3108 >;
				bias-pull-up;
			};
			uart5_tx_pb6: uart5_tx_pb6 {
				pinmux = < 0x160e >;
				bias-pull-up;
			};
			uart5_tx_pb13: uart5_tx_pb13 {
				pinmux = < 0x1d0e >;
				bias-pull-up;
			};
			uart5_tx_pc12: uart5_tx_pc12 {
				pinmux = < 0x2c08 >;
				bias-pull-up;
			};
			usart6_tx_pc6: usart6_tx_pc6 {
				pinmux = < 0x2607 >;
				bias-pull-up;
			};
			usart6_tx_pg14: usart6_tx_pg14 {
				pinmux = < 0x6e07 >;
				bias-pull-up;
			};
			uart7_tx_pa15: uart7_tx_pa15 {
				pinmux = < 0xf0b >;
				bias-pull-up;
			};
			uart7_tx_pb4: uart7_tx_pb4 {
				pinmux = < 0x140b >;
				bias-pull-up;
			};
			uart7_tx_pe8: uart7_tx_pe8 {
				pinmux = < 0x4807 >;
				bias-pull-up;
			};
			uart7_tx_pf7: uart7_tx_pf7 {
				pinmux = < 0x5707 >;
				bias-pull-up;
			};
			uart8_tx_pe1: uart8_tx_pe1 {
				pinmux = < 0x4108 >;
				bias-pull-up;
			};
			usb_otg_fs_sof_pa8: usb_otg_fs_sof_pa8 {
				pinmux = < 0x80a >;
			};
			usb_otg_fs_id_pa10: usb_otg_fs_id_pa10 {
				pinmux = < 0xa0a >;
			};
			usb_otg_fs_dm_pa11: usb_otg_fs_dm_pa11 {
				pinmux = < 0xb0a >;
			};
			usb_otg_fs_dp_pa12: usb_otg_fs_dp_pa12 {
				pinmux = < 0xc0a >;
			};
			usb_otg_hs_sof_pa4: usb_otg_hs_sof_pa4 {
				pinmux = < 0x40c >;
			};
			usb_otg_hs_id_pb12: usb_otg_hs_id_pb12 {
				pinmux = < 0x1c0c >;
			};
			usb_otg_hs_dm_pb14: usb_otg_hs_dm_pb14 {
				pinmux = < 0x1e0c >;
			};
			usb_otg_hs_dp_pb15: usb_otg_hs_dp_pb15 {
				pinmux = < 0x1f0c >;
			};
			usb_otg_hs_ulpi_d0_pa3: usb_otg_hs_ulpi_d0_pa3 {
				pinmux = < 0x30a >;
			};
			usb_otg_hs_ulpi_d1_pb0: usb_otg_hs_ulpi_d1_pb0 {
				pinmux = < 0x100a >;
			};
			usb_otg_hs_ulpi_d2_pb1: usb_otg_hs_ulpi_d2_pb1 {
				pinmux = < 0x110a >;
			};
			usb_otg_hs_ulpi_d7_pb5: usb_otg_hs_ulpi_d7_pb5 {
				pinmux = < 0x150a >;
			};
			usb_otg_hs_ulpi_d3_pb10: usb_otg_hs_ulpi_d3_pb10 {
				pinmux = < 0x1a0a >;
			};
			usb_otg_hs_ulpi_d4_pb11: usb_otg_hs_ulpi_d4_pb11 {
				pinmux = < 0x1b0a >;
			};
			usb_otg_hs_ulpi_d5_pb12: usb_otg_hs_ulpi_d5_pb12 {
				pinmux = < 0x1c0a >;
			};
			usb_otg_hs_ulpi_d6_pb13: usb_otg_hs_ulpi_d6_pb13 {
				pinmux = < 0x1d0a >;
			};
			usb_otg_hs_ulpi_stp_pc0: usb_otg_hs_ulpi_stp_pc0 {
				pinmux = < 0x200a >;
			};
			usb_otg_hs_ulpi_dir_pc2: usb_otg_hs_ulpi_dir_pc2 {
				pinmux = < 0x220a >;
			};
			usb_otg_hs_ulpi_nxt_pc3: usb_otg_hs_ulpi_nxt_pc3 {
				pinmux = < 0x230a >;
			};
		};
		wwdg1: watchdog@50003000 {
			compatible = "st,stm32-window-watchdog";
			reg = < 0x50003000 0x400 >;
			clocks = < &rcc 0xa 0x800 >;
			interrupts = < 0x0 0x7 >;
			status = "disabled";
			label = "WWDG_1";
		};
		usart1: serial@40011000 {
			compatible = "st,stm32-usart", "st,stm32-uart";
			reg = < 0x40011000 0x400 >;
			clocks = < &rcc 0x3 0x10 >;
			interrupts = < 0x25 0x0 >;
			status = "disabled";
			label = "UART_1";
		};
		usart2: serial@40004400 {
			compatible = "st,stm32-usart", "st,stm32-uart";
			reg = < 0x40004400 0x400 >;
			clocks = < &rcc 0x2 0x20000 >;
			interrupts = < 0x26 0x0 >;
			status = "disabled";
			label = "UART_2";
		};
		usart3: serial@40004800 {
			compatible = "st,stm32-usart", "st,stm32-uart";
			reg = < 0x40004800 0x400 >;
			clocks = < &rcc 0x2 0x40000 >;
			interrupts = < 0x27 0x0 >;
			status = "okay";
			label = "UART_3";
			pinctrl-0 = < &usart3_tx_pd8 &usart3_rx_pd9 >;
			current-speed = < 0x1c200 >;
		};
		uart4: serial@40004c00 {
			compatible = "st,stm32-uart";
			reg = < 0x40004c00 0x400 >;
			clocks = < &rcc 0x2 0x80000 >;
			interrupts = < 0x34 0x0 >;
			status = "disabled";
			label = "UART_4";
		};
		uart5: serial@40005000 {
			compatible = "st,stm32-uart";
			reg = < 0x40005000 0x400 >;
			clocks = < &rcc 0x2 0x100000 >;
			interrupts = < 0x35 0x0 >;
			status = "disabled";
			label = "UART_5";
		};
		usart6: serial@40011400 {
			compatible = "st,stm32-usart", "st,stm32-uart";
			reg = < 0x40011400 0x400 >;
			clocks = < &rcc 0x3 0x20 >;
			interrupts = < 0x47 0x0 >;
			status = "disabled";
			label = "UART_6";
		};
		uart7: serial@40007800 {
			compatible = "st,stm32-uart";
			reg = < 0x40007800 0x400 >;
			clocks = < &rcc 0x2 0x40000000 >;
			interrupts = < 0x52 0x0 >;
			status = "disabled";
			label = "UART_7";
		};
		uart8: serial@40007c00 {
			compatible = "st,stm32-uart";
			reg = < 0x40007c00 0x400 >;
			clocks = < &rcc 0x2 0x80000000 >;
			interrupts = < 0x53 0x0 >;
			status = "disabled";
			label = "UART_8";
		};
		rtc: rtc@58004000 {
			compatible = "st,stm32-rtc";
			reg = < 0x58004000 0x400 >;
			interrupts = < 0x29 0x0 >;
			clocks = < &rcc 0xb 0x10000 >;
			prescaler = < 0x8000 >;
			status = "okay";
			label = "RTC_0";
		};
		i2c1: arduino_i2c: i2c@40005400 {
			compatible = "st,stm32-i2c-v2";
			clock-frequency = < 0x61a80 >;
			#address-cells = < 0x1 >;
			#size-cells = < 0x0 >;
			reg = < 0x40005400 0x400 >;
			clocks = < &rcc 0x2 0x200000 >;
			interrupts = < 0x1f 0x0 >, < 0x20 0x0 >;
			interrupt-names = "event", "error";
			status = "okay";
			label = "I2C_1";
			pinctrl-0 = < &i2c1_scl_pb8 &i2c1_sda_pb9 >;
		};
		i2c2: i2c@40005800 {
			compatible = "st,stm32-i2c-v2";
			clock-frequency = < 0x186a0 >;
			#address-cells = < 0x1 >;
			#size-cells = < 0x0 >;
			reg = < 0x40005800 0x400 >;
			clocks = < &rcc 0x2 0x400000 >;
			interrupts = < 0x21 0x0 >, < 0x22 0x0 >;
			interrupt-names = "event", "error";
			status = "disabled";
			label = "I2C_2";
		};
		i2c3: i2c@40005c00 {
			compatible = "st,stm32-i2c-v2";
			clock-frequency = < 0x186a0 >;
			#address-cells = < 0x1 >;
			#size-cells = < 0x0 >;
			reg = < 0x40005c00 0x400 >;
			clocks = < &rcc 0x2 0x800000 >;
			interrupts = < 0x48 0x0 >, < 0x49 0x0 >;
			interrupt-names = "event", "error";
			status = "disabled";
			label = "I2C_3";
		};
		i2c4: i2c@58001c00 {
			compatible = "st,stm32-i2c-v2";
			clock-frequency = < 0x186a0 >;
			#address-cells = < 0x1 >;
			#size-cells = < 0x0 >;
			reg = < 0x58001c00 0x400 >;
			clocks = < &rcc 0xb 0x80 >;
			interrupts = < 0x5f 0x0 >, < 0x60 0x0 >;
			interrupt-names = "event", "error";
			status = "disabled";
			label = "I2C_4";
		};
		timers1: timers@40010000 {
			compatible = "st,stm32-timers";
			reg = < 0x40010000 0x400 >;
			clocks = < &rcc 0x3 0x1 >;
			interrupts = < 0x18 0x0 >, < 0x19 0x0 >, < 0x1a 0x0 >, < 0x1b 0x0 >;
			interrupt-names = "brk", "up", "trgcom", "cc";
			status = "disabled";
			label = "TIMERS_1";
			pwm {
				compatible = "st,stm32-pwm";
				status = "disabled";
				st,prescaler = < 0x2710 >;
				label = "PWM_1";
				#pwm-cells = < 0x3 >;
			};
		};
		timers2: timers@40000000 {
			compatible = "st,stm32-timers";
			reg = < 0x40000000 0x400 >;
			clocks = < &rcc 0x2 0x1 >;
			interrupts = < 0x1c 0x0 >;
			interrupt-names = "global";
			status = "disabled";
			label = "TIMERS_2";
			pwm {
				compatible = "st,stm32-pwm";
				status = "disabled";
				st,prescaler = < 0x0 >;
				label = "PWM_2";
				#pwm-cells = < 0x3 >;
			};
		};
		timers3: timers@40000400 {
			compatible = "st,stm32-timers";
			reg = < 0x40000400 0x400 >;
			clocks = < &rcc 0x2 0x2 >;
			interrupts = < 0x1d 0x0 >;
			interrupt-names = "global";
			status = "disabled";
			label = "TIMERS_3";
			pwm {
				compatible = "st,stm32-pwm";
				status = "disabled";
				st,prescaler = < 0x2710 >;
				label = "PWM_3";
				#pwm-cells = < 0x3 >;
			};
		};
		timers4: timers@40000800 {
			compatible = "st,stm32-timers";
			reg = < 0x40000800 0x400 >;
			clocks = < &rcc 0x2 0x4 >;
			interrupts = < 0x1e 0x0 >;
			interrupt-names = "global";
			status = "disabled";
			label = "TIMERS_4";
			pwm {
				compatible = "st,stm32-pwm";
				status = "disabled";
				st,prescaler = < 0x2710 >;
				label = "PWM_4";
				#pwm-cells = < 0x3 >;
			};
		};
		timers5: timers@40000c00 {
			compatible = "st,stm32-timers";
			reg = < 0x40000c00 0x400 >;
			clocks = < &rcc 0x2 0x8 >;
			interrupts = < 0x32 0x0 >;
			interrupt-names = "global";
			status = "disabled";
			label = "TIMERS_5";
			pwm {
				compatible = "st,stm32-pwm";
				status = "disabled";
				st,prescaler = < 0x0 >;
				label = "PWM_5";
				#pwm-cells = < 0x3 >;
			};
		};
		timers6: timers@40001000 {
			compatible = "st,stm32-timers";
			reg = < 0x40001000 0x400 >;
			clocks = < &rcc 0x2 0x10 >;
			interrupts = < 0x36 0x0 >;
			interrupt-names = "global";
			status = "disabled";
			label = "TIMERS_6";
			pwm {
				compatible = "st,stm32-pwm";
				status = "disabled";
				st,prescaler = < 0x2710 >;
				label = "PWM_6";
				#pwm-cells = < 0x3 >;
			};
		};
		timers7: timers@40001400 {
			compatible = "st,stm32-timers";
			reg = < 0x40001400 0x400 >;
			clocks = < &rcc 0x2 0x20 >;
			interrupts = < 0x37 0x0 >;
			interrupt-names = "global";
			status = "disabled";
			label = "TIMERS_7";
			pwm {
				compatible = "st,stm32-pwm";
				status = "disabled";
				st,prescaler = < 0x2710 >;
				label = "PWM_7";
				#pwm-cells = < 0x3 >;
			};
		};
		timers8: timers@40010400 {
			compatible = "st,stm32-timers";
			reg = < 0x40010400 0x400 >;
			clocks = < &rcc 0x3 0x2 >;
			interrupts = < 0x2b 0x0 >, < 0x2c 0x0 >, < 0x2d 0x0 >, < 0x2e 0x0 >;
			interrupt-names = "brk", "up", "trgcom", "cc";
			status = "disabled";
			label = "TIMERS_8";
			pwm {
				compatible = "st,stm32-pwm";
				status = "disabled";
				st,prescaler = < 0x2710 >;
				label = "PWM_8";
				#pwm-cells = < 0x3 >;
			};
		};
		timers12: timers@40001800 {
			compatible = "st,stm32-timers";
			reg = < 0x40001800 0x400 >;
			clocks = < &rcc 0x2 0x40 >;
			interrupts = < 0x2b 0x0 >;
			interrupt-names = "global";
			status = "okay";
			label = "TIMERS_12";
			pwm12: pwm {
				compatible = "st,stm32-pwm";
				status = "okay";
				st,prescaler = < 0x2710 >;
				label = "PWM_12";
				#pwm-cells = < 0x3 >;
				pinctrl-0 = < &tim12_ch1_pwm_pb14 >;
				phandle = < 0x10 >;
			};
		};
		timers13: timers@40001c00 {
			compatible = "st,stm32-timers";
			reg = < 0x40001c00 0x400 >;
			clocks = < &rcc 0x2 0x80 >;
			interrupts = < 0x2c 0x0 >;
			interrupt-names = "global";
			status = "disabled";
			label = "TIMERS_13";
			pwm {
				compatible = "st,stm32-pwm";
				status = "disabled";
				st,prescaler = < 0x2710 >;
				label = "PWM_13";
				#pwm-cells = < 0x3 >;
			};
		};
		timers14: timers@40002000 {
			compatible = "st,stm32-timers";
			reg = < 0x40002000 0x400 >;
			clocks = < &rcc 0x2 0x100 >;
			interrupts = < 0x2d 0x0 >;
			interrupt-names = "global";
			status = "disabled";
			label = "TIMERS_14";
			pwm {
				compatible = "st,stm32-pwm";
				status = "disabled";
				st,prescaler = < 0x2710 >;
				label = "PWM_14";
				#pwm-cells = < 0x3 >;
			};
		};
		timers15: timers@40014000 {
			compatible = "st,stm32-timers";
			reg = < 0x40014000 0x400 >;
			clocks = < &rcc 0x3 0x10000 >;
			interrupts = < 0x74 0x0 >;
			interrupt-names = "global";
			status = "disabled";
			label = "TIMERS_15";
			pwm {
				compatible = "st,stm32-pwm";
				status = "disabled";
				st,prescaler = < 0x2710 >;
				label = "PWM_15";
				#pwm-cells = < 0x3 >;
			};
		};
		timers16: timers@40014400 {
			compatible = "st,stm32-timers";
			reg = < 0x40014400 0x400 >;
			clocks = < &rcc 0x3 0x20000 >;
			interrupts = < 0x75 0x0 >;
			interrupt-names = "global";
			status = "disabled";
			label = "TIMERS_16";
			pwm {
				compatible = "st,stm32-pwm";
				status = "disabled";
				st,prescaler = < 0x2710 >;
				label = "PWM_16";
				#pwm-cells = < 0x3 >;
			};
		};
		timers17: timers@40014800 {
			compatible = "st,stm32-timers";
			reg = < 0x40014800 0x400 >;
			clocks = < &rcc 0x3 0x40000 >;
			interrupts = < 0x76 0x0 >;
			interrupt-names = "global";
			status = "disabled";
			label = "TIMERS_17";
			pwm {
				compatible = "st,stm32-pwm";
				status = "disabled";
				st,prescaler = < 0x2710 >;
				label = "PWM_17";
				#pwm-cells = < 0x3 >;
			};
		};
		adc1: adc@40022000 {
			compatible = "st,stm32-adc";
			reg = < 0x40022000 0x400 >;
			clocks = < &rcc 0x0 0x20 >;
			interrupts = < 0x12 0x0 >;
			status = "okay";
			label = "ADC_1";
			#io-channel-cells = < 0x1 >;
			pinctrl-0 = < &adc1_inp15_pa3 >;
		};
		adc2: adc@40022100 {
			compatible = "st,stm32-adc";
			reg = < 0x40022100 0x400 >;
			clocks = < &rcc 0x0 0x20 >;
			interrupts = < 0x12 0x0 >;
			status = "disabled";
			label = "ADC_2";
			#io-channel-cells = < 0x1 >;
		};
		adc1_2: adc@40022300 {
			compatible = "st,stm32-adc";
			reg = < 0x40022300 0x400 >;
			clocks = < &rcc 0x0 0x20 >;
			interrupts = < 0x12 0x0 >;
			status = "disabled";
			label = "ADC_1_2";
			#io-channel-cells = < 0x1 >;
		};
		adc3: adc@58026000 {
			compatible = "st,stm32-adc";
			reg = < 0x58026000 0x400 >;
			clocks = < &rcc 0x7 0x1000000 >;
			interrupts = < 0x7f 0x0 >;
			status = "disabled";
			label = "ADC_3";
			#io-channel-cells = < 0x1 >;
		};
		dma1: dma@40020000 {
			compatible = "st,stm32-dma";
			#dma-cells = < 0x4 >;
			reg = < 0x40020000 0x400 >;
			interrupts = < 0xb 0x0 >, < 0xc 0x0 >, < 0xd 0x0 >, < 0xe 0x0 >, < 0xf 0x0 >, < 0x10 0x0 >, < 0x11 0x0 >, < 0x2f 0x0 >;
			clocks = < &rcc 0x0 0x20 >;
			status = "disabled";
			label = "DMA_1";
		};
		dma2: dma@40020400 {
			compatible = "st,stm32-dma";
			#dma-cells = < 0x4 >;
			reg = < 0x40020400 0x400 >;
			interrupts = < 0xb 0x0 >, < 0xc 0x0 >, < 0xd 0x0 >, < 0xe 0x0 >, < 0xf 0x0 >, < 0x10 0x0 >, < 0x11 0x0 >, < 0x2f 0x0 >;
			clocks = < &rcc 0x0 0x20 >;
			status = "disabled";
			label = "DMA_2";
		};
		rng: rng@48021800 {
			compatible = "st,stm32-rng";
			reg = < 0x48021800 0x400 >;
			clocks = < &rcc 0x1 0x40 >;
			interrupts = < 0x50 0x0 >;
			status = "okay";
			label = "RNG";
		};
		mac: ethernet@40028000 {
			compatible = "st,stm32-ethernet";
			reg = < 0x40028000 0x8000 >;
			label = "ETH_0";
			interrupts = < 0x3d 0x0 >;
			clock-names = "stmmaceth", "mac-clk-tx", "mac-clk-rx";
			clocks = < &rcc 0x0 0x8000 >, < &rcc 0x0 0x10000 >, < &rcc 0x0 0x20000 >;
			status = "disabled";
		};
	};
	cpus {
		#address-cells = < 0x1 >;
		#size-cells = < 0x0 >;
		cpu@0 {
			device_type = "cpu";
			compatible = "arm,cortex-m7";
			reg = < 0x0 >;
			#address-cells = < 0x1 >;
			#size-cells = < 0x1 >;
			mpu: mpu@e000ed90 {
				compatible = "arm,armv7m-mpu";
				reg = < 0xe000ed90 0x40 >;
				arm,num-mpu-regions = < 0x10 >;
			};
		};
	};
	sram0: memory@24000000 {
		compatible = "mmio-sram";
		reg = < 0x24000000 0x80000 >;
	};
	dtcm: memory@20000000 {
		compatible = "arm,dtcm";
		reg = < 0x20000000 0x20000 >;
	};
	arduino_header: connector {
		compatible = "arduino-header-r3";
		#gpio-cells = < 0x2 >;
		gpio-map-mask = < 0xffffffff 0xffffffc0 >;
		gpio-map-pass-thru = < 0x0 0x3f >;
		gpio-map = < 0x0 0x0 &gpioa 0x3 0x0 >, < 0x1 0x0 &gpioc 0x0 0x0 >, < 0x2 0x0 &gpioc 0x3 0x0 >, < 0x3 0x0 &gpiob 0x1 0x0 >, < 0x4 0x0 &gpioc 0x2 0x0 >, < 0x5 0x0 &gpiof 0xa 0x0 >, < 0x6 0x0 &gpiob 0x7 0x0 >, < 0x7 0x0 &gpiob 0x6 0x0 >, < 0x8 0x0 &gpiog 0xe 0x0 >, < 0x9 0x0 &gpioe 0xd 0x0 >, < 0xa 0x0 &gpioe 0xe 0x0 >, < 0xb 0x0 &gpioe 0xb 0x0 >, < 0xc 0x0 &gpioe 0x9 0x0 >, < 0xd 0x0 &gpiog 0xc 0x0 >, < 0xe 0x0 &gpiof 0x3 0x0 >, < 0xf 0x0 &gpiod 0xf 0x0 >, < 0x10 0x0 &gpiod 0xe 0x0 >, < 0x11 0x0 &gpiob 0x5 0x0 >, < 0x12 0x0 &gpioa 0x6 0x0 >, < 0x13 0x0 &gpioa 0x5 0x0 >, < 0x14 0x0 &gpiob 0x9 0x0 >, < 0x15 0x0 &gpiob 0x8 0x0 >;
	};
	leds {
		compatible = "gpio-leds";
		green_led: led_0 {
			gpios = < &gpiob 0x0 0x0 >;
			label = "User LD1";
		};
		blue_led: led_1 {
			gpios = < &gpiob 0x7 0x0 >;
			label = "User LD2";
		};
	};
	pwmleds {
		compatible = "pwm-leds";
		red_pwm_led: red_pwm_led {
			pwms = < &pwm12 0x1 0x4 0x0 >;
		};
	};
	gpio_keys {
		compatible = "gpio-keys";
		user_button: button_0 {
			label = "User";
			gpios = < &gpioc 0xd 0x0 >;
		};
	};
};
